VERSION "Excel 2 DBC"

NS_ :

BS_:

BU_: Stress

BO_ 88888888 StressExtended1: 8 Stress
 SG_ Counter : 0|32@1+ (1,0) [0|0] "" Vector__XXX

BO_ 1541 Info5: 8 Stress
 SG_ Counter : 32|16@1+ (1,0) [0|0] "" Vector__XXX
 SG_ CurrentCycle : 0|32@1+ (0.01,0) [0.5|1000] "ms" Vector__XXX

BO_ 1540 Info4: 8 Stress
 SG_ Counter : 32|16@1+ (1,0) [0|0] "" Vector__XXX
 SG_ CurrentCycle : 0|32@1+ (0.01,0) [0.5|1000] "ms" Vector__XXX

BO_ 1539 Info3: 8 Stress
 SG_ Counter : 32|16@1+ (1,0) [0|0] "" Vector__XXX
 SG_ CurrentCycle : 0|32@1+ (0.01,0) [0.5|1000] "ms" Vector__XXX

BO_ 1538 Info2: 8 Stress
 SG_ Counter : 32|16@1+ (1,0) [0|0] "" Vector__XXX
 SG_ CurrentCycle : 0|32@1+ (0.01,0) [0.5|1000] "ms" Vector__XXX

BO_ 1537 Info1: 8 Stress
 SG_ Counter : 32|16@1+ (1,0) [0|0] "" Vector__XXX
 SG_ CurrentCycle : 0|32@1+ (0.01,0) [0.5|1000] "ms" Vector__XXX

BO_ 1536 InfoStress1: 8 Stress
 SG_ Counter : 32|16@1+ (1,0) [0|0] "" Vector__XXX
 SG_ CurrentCycle : 0|32@1+ (0.01,0) [0.5|1000] "ms" Vector__XXX

BO_ 289 Stress4: 5 Stress
 SG_ BurstCount : 32|8@1+ (1,0) [0|0] "" Vector__XXX
 SG_ Counter : 0|16@1+ (1,0) [0|0] "" Vector__XXX

BO_ 288 Stress3: 5 Stress
 SG_ BurstCount : 32|8@1+ (1,0) [0|0] "" Vector__XXX
 SG_ Counter : 0|16@1+ (1,0) [0|0] "" Vector__XXX

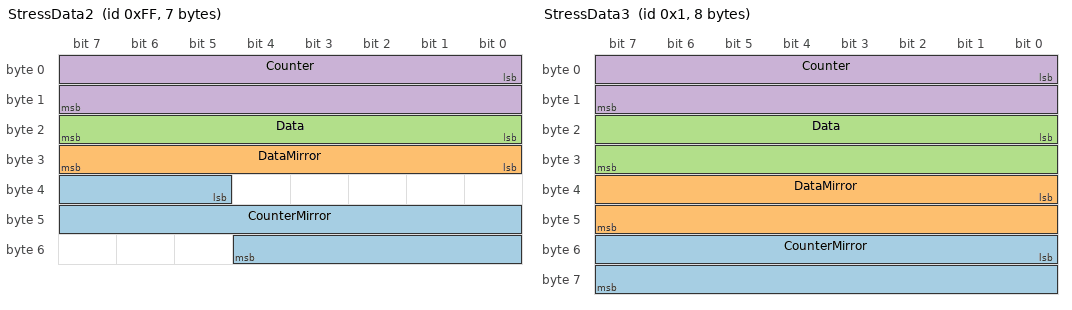
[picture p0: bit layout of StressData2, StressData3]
BO_ 255 StressData2: 7 Stress
 SG_ CounterMirror : 37|16@1+ (1,0) [0|0] "" Vector__XXX
 SG_ DataMirror : 24|8@1+ (1,0) [0|0] "" Vector__XXX
 SG_ Data : 16|8@1+ (1,0) [0|0] "" Vector__XXX
 SG_ Counter : 0|16@1+ (1,0) [0|0] "" Vector__XXX

BO_ 52 Stress5: 5 Stress
 SG_ BurstCount : 32|8@1+ (1,0) [0|0] "" Vector__XXX
 SG_ Counter : 0|32@1+ (1,0) [0|0] "NUMS" Vector__XXX

BO_ 42 Stress20: 5 Stress
 SG_ BurstCount : 32|8@1+ (1,0) [0|0] "" Vector__XXX
 SG_ Counter : 0|32@1+ (1,0) [0|0] "NUMS" Vector__XXX

BO_ 41 Stress19: 5 Stress
 SG_ BurstCount : 32|8@1+ (1,0) [0|0] "" Vector__XXX
 SG_ Counter : 0|32@1+ (1,0) [0|0] "NUMS" Vector__XXX

BO_ 40 Stress18: 5 Stress
 SG_ BurstCount : 32|8@1+ (1,0) [0|0] "" Vector__XXX
 SG_ Counter : 0|32@1+ (1,0) [0|0] "NUMS" Vector__XXX

BO_ 39 Stress17: 5 Stress
 SG_ BurstCount : 32|8@1+ (1,0) [0|0] "" Vector__XXX
 SG_ Counter : 0|32@1+ (1,0) [0|0] "NUMS" Vector__XXX

BO_ 38 Stress16: 5 Stress
 SG_ BurstCount : 32|8@1+ (1,0) [0|0] "" Vector__XXX
 SG_ Counter : 0|32@1+ (1,0) [0|0] "NUMS" Vector__XXX

BO_ 37 Stress15: 5 Stress
 SG_ BurstCount : 32|8@1+ (1,0) [0|0] "" Vector__XXX
 SG_ Counter : 0|32@1+ (1,0) [0|0] "NUMS" Vector__XXX

BO_ 36 Stress14: 5 Stress
 SG_ BurstCount : 32|8@1+ (1,0) [0|0] "" Vector__XXX
 SG_ Counter : 0|32@1+ (1,0) [0|0] "NUMS" Vector__XXX

BO_ 35 Stress13: 5 Stress
 SG_ BurstCount : 32|8@1+ (1,0) [0|0] "" Vector__XXX
 SG_ Counter : 0|32@1+ (1,0) [0|0] "NUMS" Vector__XXX

BO_ 34 Stress12: 5 Stress
 SG_ BurstCount : 32|8@1+ (1,0) [0|0] "" Vector__XXX
 SG_ Counter : 0|32@1+ (1,0) [0|0] "NUMS" Vector__XXX

BO_ 33 Stress11: 5 Stress
 SG_ BurstCount : 32|8@1+ (1,0) [0|0] "" Vector__XXX
 SG_ Counter : 0|32@1+ (1,0) [0|0] "NUMS" Vector__XXX

BO_ 32 Stress10: 5 Stress
 SG_ BurstCount : 32|8@1+ (1,0) [0|0] "" Vector__XXX
 SG_ Counter : 0|32@1+ (1,0) [0|0] "NUMS" Vector__XXX

BO_ 25 Stress9: 5 Stress
 SG_ BurstCount : 32|8@1+ (1,0) [0|0] "" Vector__XXX
 SG_ Counter : 0|32@1+ (1,0) [0|0] "NUMS" Vector__XXX

BO_ 24 Stress8: 5 Stress
 SG_ BurstCount : 32|8@1+ (1,0) [0|0] "" Vector__XXX
 SG_ Counter : 0|32@1+ (1,0) [0|0] "NUMS" Vector__XXX

BO_ 23 Stress7: 5 Stress
 SG_ BurstCount : 32|8@1+ (1,0) [0|0] "" Vector__XXX
 SG_ Counter : 0|32@1+ (1,0) [0|0] "NUMS" Vector__XXX

BO_ 22 Stress6: 5 Stress
 SG_ BurstCount : 32|8@1+ (1,0) [0|0] "" Vector__XXX
 SG_ Counter : 0|32@1+ (1,0) [0|0] "NUMS" Vector__XXX

BO_ 18 Stress2: 5 Stress
 SG_ BurstCount : 32|8@1+ (1,0) [0|0] "" Vector__XXX
 SG_ Counter : 0|16@1+ (1,0) [0|0] "" Vector__XXX

BO_ 13 Stress1: 5 Stress
 SG_ BurstCount : 32|8@1+ (1,0) [0|0] "" Vector__XXX
 SG_ Counter : 0|32@1+ (1,0) [0|0] "NUMS" Vector__XXX

BO_ 12 HiPrStress3: 6 Stress
 SG_ BurstCount : 32|8@1+ (1,0) [0|0] "" Vector__XXX
 SG_ Counter : 0|32@1+ (1,0) [0|0] "NUMS" Vector__XXX

BO_ 11 HiPrStress2: 6 Stress
 SG_ BurstCount : 32|8@1+ (1,0) [0|0] "" Vector__XXX
 SG_ Counter : 0|32@1+ (1,0) [0|0] "NUMS" Vector__XXX

BO_ 10 HiPrStress1: 5 Stress
 SG_ BurstCount : 32|8@1+ (1,0) [0|0] "" Vector__XXX
 SG_ Counter : 0|32@1+ (1,0) [0|0] "NUMS" Vector__XXX

BO_ 3 StressData4: 1 Stress
 SG_ CounterMirror : 4|4@1+ (1,0) [0|0] "" Vector__XXX
 SG_ Counter : 0|4@1+ (1,0) [0|0] "" Vector__XXX

BO_ 1 StressData3: 8 Stress
 SG_ CounterMirror : 48|16@1+ (1,0) [0|0] "" Vector__XXX
 SG_ DataMirror : 32|16@1+ (1,0) [0|0] "" Vector__XXX
 SG_ Data : 16|16@1+ (1,0) [0|0] "" Vector__XXX
 SG_ Counter : 0|16@1+ (1,0) [0|0] "" Vector__XXX

BO_ 85 StressExtended2: 4 Stress
 SG_ Counter : 0|32@1+ (1,0) [0|0] "" Vector__XXX

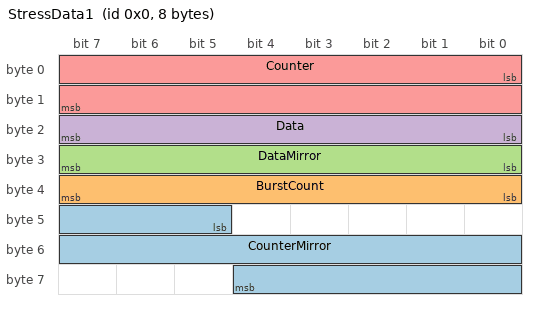
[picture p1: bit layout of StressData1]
BO_ 0 StressData1: 8 Stress
 SG_ CounterMirror : 45|16@1+ (1,0) [0|0] "" Vector__XXX
 SG_ BurstCount : 32|8@1+ (1,0) [0|0] "" Vector__XXX
 SG_ DataMirror : 24|8@1+ (1,0) [0|0] "" Vector__XXX
 SG_ Data : 16|8@1+ (1,0) [0|0] "" Vector__XXX
 SG_ Counter : 0|16@1+ (1,0) [0|0] "" Vector__XXX

BA_DEF_ SG_ "GenSigStartValue" FLOAT 0 100000000000;
BA_ "GenSigStartValue" SG_ 1541 CurrentCycle 50;
BA_ "GenSigStartValue" SG_ 1540 CurrentCycle 50;
BA_ "GenSigStartValue" SG_ 1539 CurrentCycle 50;
BA_ "GenSigStartValue" SG_ 1538 CurrentCycle 50;
BA_ "GenSigStartValue" SG_ 1537 CurrentCycle 50;
BA_ "GenSigStartValue" SG_ 1536 CurrentCycle 50;
